# CY8C5868AXI_LP035 register map
File version: 0.1
CY8C58LP
Registers are 8-bit, read-write, no defined reset value unless marked. A register's access mark holds for its fields unless they carry their own. Offsets are from the block's base; lines under a group give offsets from that group; [hi:lo] are bit positions; {n}, {i} and the like mark numbered series; 'fields as' and 'values as' point back to an identical list; <NAME> marks a mode.

## Memory map
0x40004381 SleepTimer size 0x2
0x40004614 ADC_SAR_1 size 0x158D — SAR ADC
0x400049C8 NEOMOTE_1_I2C_0 size 0x19
0x40006422 uart_ultrasonic size 0x144 — UART
0x4000642C NEOMOTE_1_UART_MOTE size 0x139 — UART
0x4000642D uart_solinst size 0x13D — UART
0x40006447 uart size 0x125
0x40006471 ControlReg_Solinst size 0x1
0x40006566 BottleCount size 0x31
0x40006579 ControlReg_Modem size 0x1

## ControlReg_Solinst
Base 0x40006471
0x00 ControlReg_Solinst_CONTROL_REG

## BottleCount
Base 0x40006566
0x00 BottleCount_STATUS_REG
0x20 BottleCount_MASK_REG
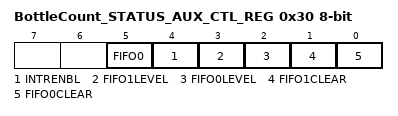
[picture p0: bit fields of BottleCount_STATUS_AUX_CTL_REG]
0x30 BottleCount_STATUS_AUX_CTL_REG
  [5] FIFO0 — FIFO0 clear
    1=ENABLED (Enable counter); 0=DISABLED (Disable counter)
  [4] INTRENBL — Enables or disables the Interrupt
    1=ENABLED (Interrupt enabled); 0=DISABLED (Interrupt disabled)
  [3] FIFO1LEVEL — FIFO level
    1=ENABLED (FIFO LVL: input mode: FIFO at least 1/2 empty; output mode: FIFO at least 1/2 full); 0=DISABLED (FIFO LVL: input mode: FIFO not full; output mode: FIFO not empty)
  [2] FIFO0LEVEL — FIFO level
    values as FIFO1LEVEL
  [1] FIFO1CLEAR — FIFO clear
    1=ENABLED (Clear FIFO state); 0=DISABLED (Normal FIFO operation)
  [0] FIFO0CLEAR — FIFO clear
    values as FIFO1CLEAR

## uart_ultrasonic — UART
Base 0x40006422
0x00 RX_uart_ultrasonic_RX_ADDRESS1 — RX Address1 Register
0x10 RX_uart_ultrasonic_RX_ADDRESS2 — RX Address2 Register
0x20 RX_uart_ultrasonic_RX_DATA — RX Data Register
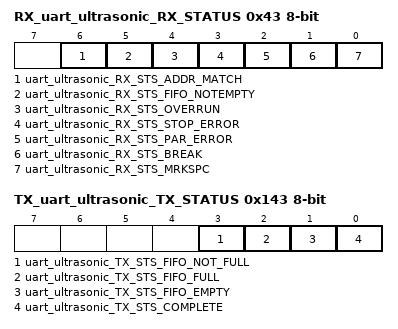
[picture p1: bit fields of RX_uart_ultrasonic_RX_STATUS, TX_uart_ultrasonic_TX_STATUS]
0x43 RX_uart_ultrasonic_RX_STATUS — RX status register
  [6] uart_ultrasonic_RX_STS_ADDR_MATCH ro, [5] uart_ultrasonic_RX_STS_FIFO_NOTEMPTY ro, [4] uart_ultrasonic_RX_STS_OVERRUN ro, [3] uart_ultrasonic_RX_STS_STOP_ERROR ro, [2] uart_ultrasonic_RX_STS_PAR_ERROR ro, [1] uart_ultrasonic_RX_STS_BREAK ro, [0] uart_ultrasonic_RX_STS_MRKSPC ro
0x123 TX_uart_ultrasonic_TX_DATA — TX Data Register
0x143 TX_uart_ultrasonic_TX_STATUS — TX status register
  [3] uart_ultrasonic_TX_STS_FIFO_NOT_FULL ro, [2] uart_ultrasonic_TX_STS_FIFO_FULL ro, [1] uart_ultrasonic_TX_STS_FIFO_EMPTY ro, [0] uart_ultrasonic_TX_STS_COMPLETE ro

## uart
Base 0x40006447
0x00 TX_uart_TX_DATA — TX Data Register
0xE4 RX_uart_RX_ADDRESS1 — RX Address1 Register
0xF4 RX_uart_RX_ADDRESS2 — RX Address2 Register
0x104 RX_uart_RX_DATA — RX Data Register
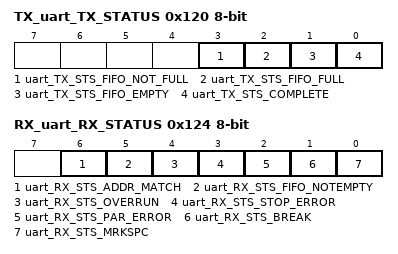
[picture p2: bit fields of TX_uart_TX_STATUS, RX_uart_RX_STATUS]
0x120 TX_uart_TX_STATUS — TX status register
  [3] uart_TX_STS_FIFO_NOT_FULL ro, [2] uart_TX_STS_FIFO_FULL ro, [1] uart_TX_STS_FIFO_EMPTY ro, [0] uart_TX_STS_COMPLETE ro
0x124 RX_uart_RX_STATUS — RX status register
  [6] uart_RX_STS_ADDR_MATCH ro, [5] uart_RX_STS_FIFO_NOTEMPTY ro, [4] uart_RX_STS_OVERRUN ro, [3] uart_RX_STS_STOP_ERROR ro, [2] uart_RX_STS_PAR_ERROR ro, [1] uart_RX_STS_BREAK ro, [0] uart_RX_STS_MRKSPC ro

## ADC_SAR_1 — SAR ADC
Base 0x40004614
0x00 SAR_TR0 — SAR trim register
{0x12EC+i} SAR_CSR{i} (i=0..6) — SAR status and control register {i}
0x150C SAR_SW0 — SAR Analog Routing Register 0
{0x150C+i} SAR_SW{i} (i=2..4) — SAR Analog Routing Register {i}
0x1512 SAR_SW6 — SAR Analog Routing Register 6
0x1513 SAR_CLK — SAR Clock Selection Register
0x158C SAR_WRK 16-bit — SAR working register

## NEOMOTE_1_I2C_0
Base 0x400049C8
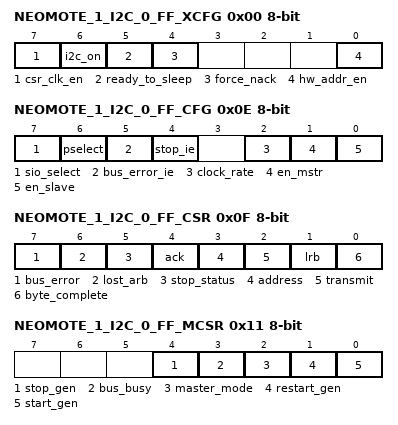
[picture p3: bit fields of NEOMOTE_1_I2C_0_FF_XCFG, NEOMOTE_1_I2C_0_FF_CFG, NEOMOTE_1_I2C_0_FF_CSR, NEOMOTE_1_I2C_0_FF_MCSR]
0x00 NEOMOTE_1_I2C_0_FF_XCFG — Extended Configuration Register: I2C_XCFG
  [7] csr_clk_en, [6] i2c_on, [5] ready_to_sleep ro, [4] force_nack, [0] hw_addr_en
0x02 NEOMOTE_1_I2C_0_FF_ADDR — Slave Adddress Register: I2C_ADR
  [6:0] slave_address — This register holds the slave's 7-bit address.
0x0E NEOMOTE_1_I2C_0_FF_CFG — Configuration Register: I2C_CFG
  [7] sio_select, [6] pselect, [5] bus_error_ie, [4] stop_ie, [2] clock_rate, [1] en_mstr, [0] en_slave
0x0F NEOMOTE_1_I2C_0_FF_CSR — Control and Status Register: I2C_CSR
  [7] bus_error, [6] lost_arb, [5] stop_status, [4] ack, [3] address, [2] transmit, [1] lrb, [0] byte_complete
0x10 NEOMOTE_1_I2C_0_FF_DATA — Data Register: I2C_D
  [7:0] data — This register provides read/write access to the Shift register.
0x11 NEOMOTE_1_I2C_0_FF_MCSR — Master Control and Status Register: I2C_MCSR
  [4] stop_gen, [3] bus_busy ro, [2] master_mode ro, [1] restart_gen, [0] start_gen
0x13 NEOMOTE_1_I2C_0_FF__CLK_DIV1 — Divider of BUS_CLK low part: I2C_CLK_DIV1
  [7:0] Div
0x14 NEOMOTE_1_I2C_0_FF__CLK_DIV2 — Divider high part: I2C_CLK_DIV1
  [1:0] Div
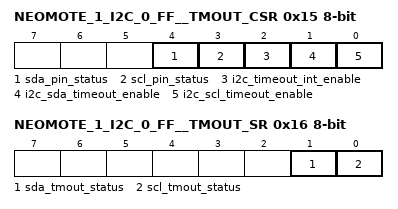
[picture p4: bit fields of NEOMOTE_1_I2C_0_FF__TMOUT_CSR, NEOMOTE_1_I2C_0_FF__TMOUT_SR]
0x15 NEOMOTE_1_I2C_0_FF__TMOUT_CSR — Extended Configuration Register: I2C_TMOUT_CSR
  [4] sda_pin_status, [3] scl_pin_status, [2] i2c_timeout_int_enable ro, [1] i2c_sda_timeout_enable, [0] i2c_scl_timeout_enable
0x16 NEOMOTE_1_I2C_0_FF__TMOUT_SR — Extended Configuration Register: I2C_TMOUT_SR
  [1] sda_tmout_status, [0] scl_tmout_status
0x17 NEOMOTE_1_I2C_0_FF__TMOUT_CFG0 — Extended Configuration Register: TMOUT_CFG0
  [7:0] timeout_period_lowbyte
0x18 NEOMOTE_1_I2C_0_FF__TMOUT_CFG1 — Extended Configuration Register: TMOUT_CFG1
  [3:0] timeout_period_highnibble

## NEOMOTE_1_UART_MOTE — UART
Base 0x4000642C
0x00 RX_NEOMOTE_1_UART_MOTE_RX_ADDRESS1 — RX Address1 Register
0x10 RX_NEOMOTE_1_UART_MOTE_RX_ADDRESS2 — RX Address2 Register
0x20 RX_NEOMOTE_1_UART_MOTE_RX_DATA — RX Data Register
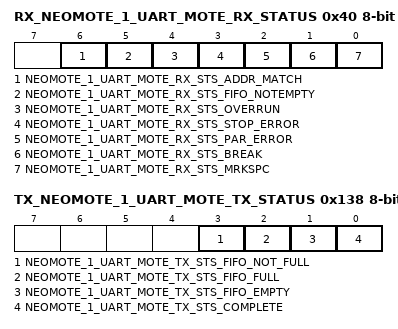
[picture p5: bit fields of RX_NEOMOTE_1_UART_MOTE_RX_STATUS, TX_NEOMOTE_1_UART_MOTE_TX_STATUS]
0x40 RX_NEOMOTE_1_UART_MOTE_RX_STATUS — RX status register
  [6] NEOMOTE_1_UART_MOTE_RX_STS_ADDR_MATCH ro, [5] NEOMOTE_1_UART_MOTE_RX_STS_FIFO_NOTEMPTY ro, [4] NEOMOTE_1_UART_MOTE_RX_STS_OVERRUN ro, [3] NEOMOTE_1_UART_MOTE_RX_STS_STOP_ERROR ro, [2] NEOMOTE_1_UART_MOTE_RX_STS_PAR_ERROR ro, [1] NEOMOTE_1_UART_MOTE_RX_STS_BREAK ro, [0] NEOMOTE_1_UART_MOTE_RX_STS_MRKSPC ro
0x118 TX_NEOMOTE_1_UART_MOTE_TX_DATA — TX Data Register
0x138 TX_NEOMOTE_1_UART_MOTE_TX_STATUS — TX status register
  [3] NEOMOTE_1_UART_MOTE_TX_STS_FIFO_NOT_FULL ro, [2] NEOMOTE_1_UART_MOTE_TX_STS_FIFO_FULL ro, [1] NEOMOTE_1_UART_MOTE_TX_STS_FIFO_EMPTY ro, [0] NEOMOTE_1_UART_MOTE_TX_STS_COMPLETE ro

## uart_solinst — UART
Base 0x4000642D
Registers as NEOMOTE_1_UART_MOTE (with NEOMOTE_1_UART_MOTE read as uart_solinst), without TX_NEOMOTE_1_UART_MOTE_TX_DATA, TX_NEOMOTE_1_UART_MOTE_TX_STATUS; these are added or differ:
0x11C TX_uart_solinst_TX_DATA — TX Data Register
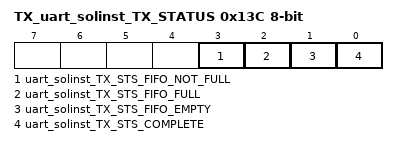
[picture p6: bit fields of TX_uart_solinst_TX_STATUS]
0x13C TX_uart_solinst_TX_STATUS — TX status register
  [3] uart_solinst_TX_STS_FIFO_NOT_FULL ro, [2] uart_solinst_TX_STS_FIFO_FULL ro, [1] uart_solinst_TX_STS_FIFO_EMPTY ro, [0] uart_solinst_TX_STS_COMPLETE ro

## SleepTimer
Base 0x40004381
0x00 SleepTimer_CTW_INTERVAL_REG — Timewheel Configuration Register 1
  [3:0] ctw_interval — Sets the central timewheel interval.
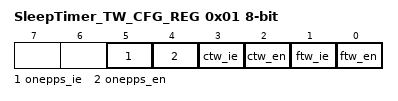
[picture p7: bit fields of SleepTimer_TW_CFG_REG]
0x01 SleepTimer_TW_CFG_REG — Timewheel Configuration Register 2
  [5] onepps_ie — When set and one pulse-per-second is enabled, an interrupt is issued when the pulse occurs.
    1=Enabled (One PPS interrupt is enabled); 0=Disabled (One PPS interrupt is disabled)
  [4] onepps_en — When set, the system returns to the active global power mode once every second.
    1=Enabled (One PPS is enabled); 0=Disabled (One PPS is disabled)
  [3] ctw_ie — When set and the central timewheel is enabled, an interrupt is issued when the central timewheel reaches the selected interval.
    1=Enabled (CTW interrupt is enabled); 0=Disabled (CTW interrupt is disabled)
  [2] ctw_en — When set, the system returns to the active global power mode when the central timewheel reaches the selected interval.
    1=Enabled (CTW is enabled); 0=Disabled (CTW is disabled)
  [1] ftw_ie — When set and the fast timewheel is enabled, an interrupt is issued when it reaches the terminal count.
    1=Enabled (FTW interrupt is enabled); 0=Disabled (FTW interrupt is disabled)
  [0] ftw_en — When set, the system returns to the active global power mode when the fast timewheel reaches the selected interval.
    1=Enabled (FTW is enabled); 0=Disabled (FTW is disabled)

## ControlReg_Modem
Base 0x40006579
Registers as ControlReg_Solinst (with ControlReg_Solinst read as ControlReg_Modem).
